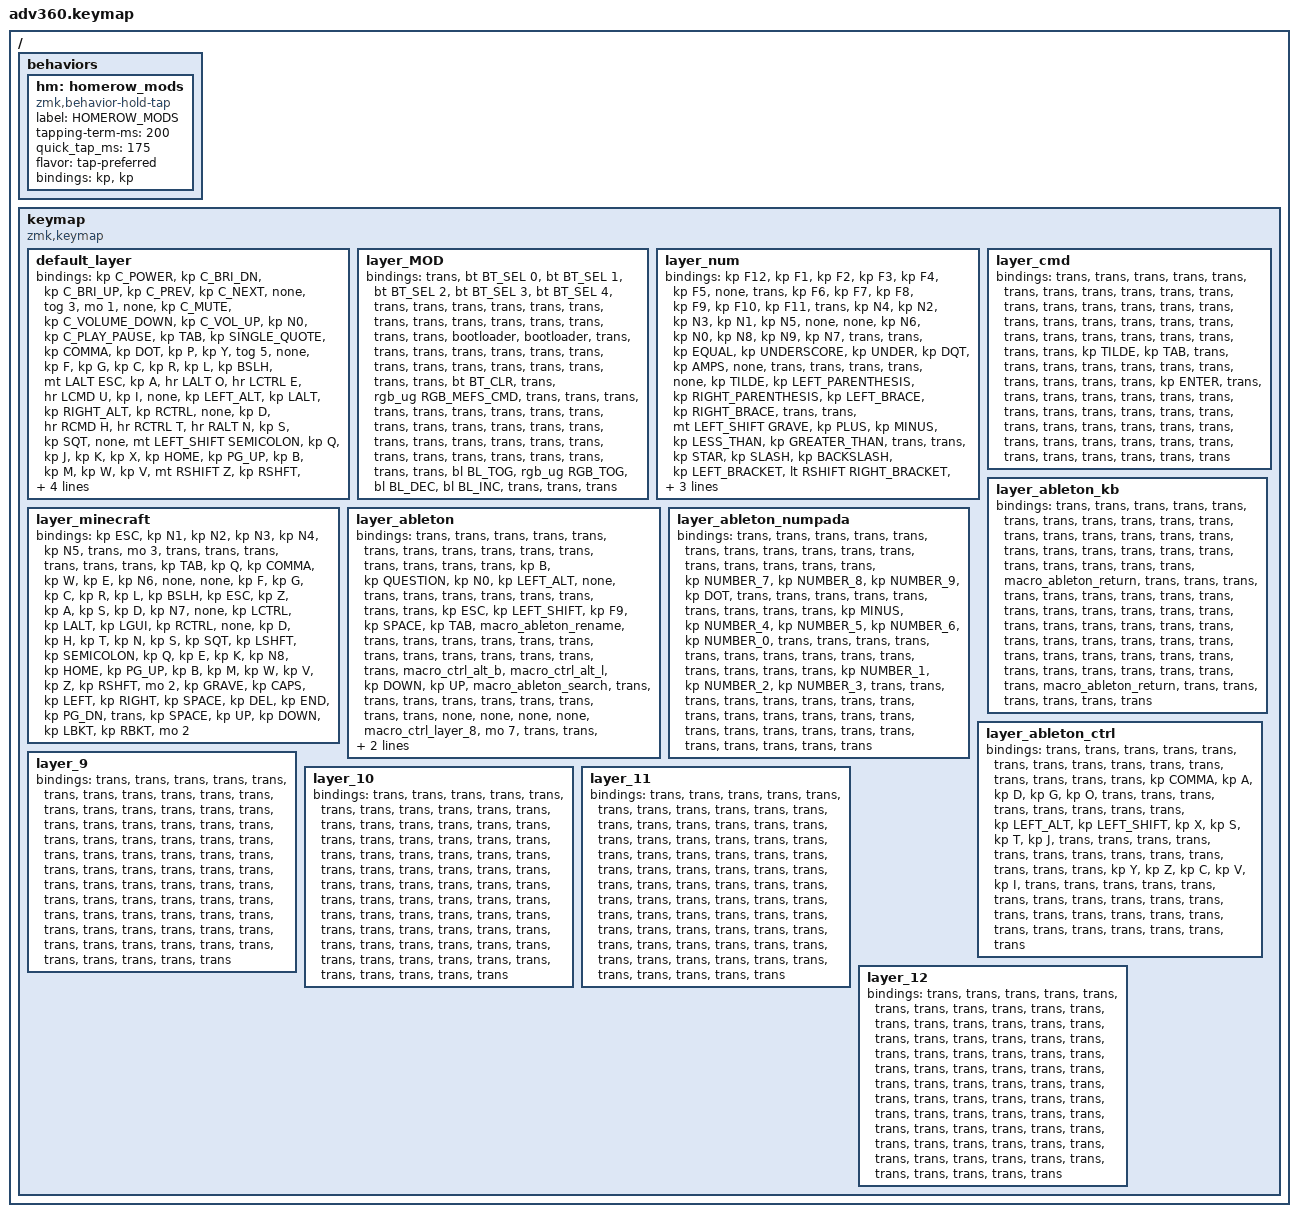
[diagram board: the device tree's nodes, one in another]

/*
 * Copyright (c) 2020 The ZMK Contributors
 *
 * SPDX-License-Identifier: MIT
 */


/* THIS FILE WAS GENERATED!
 *
 * This file was generated automatically. You may or may not want to
 * edit it directly.
 */

#include <behaviors.dtsi>
#include <dt-bindings/zmk/keys.h>
#include <dt-bindings/zmk/bt.h>
#include <dt-bindings/zmk/rgb.h>
#include <dt-bindings/zmk/backlight.h>

/ {
  behaviors {
    #include "macros.dtsi"
    #include "version.dtsi"

    hm: homerow_mods {
        compatible = "zmk,behavior-hold-tap";
        label = "HOMEROW_MODS";
        #binding-cells = <2>;
        tapping-term-ms = <200>;
        quick_tap_ms = <175>;
        flavor = "tap-preferred";
        bindings = <&kp>, <&kp>;
    };
  };

    keymap {
        compatible = "zmk,keymap";


        default_layer {
            bindings = <
         &kp C_POWER              &kp C_BRI_DN  &kp C_BRI_UP  &kp C_PREV  &kp C_NEXT   &none                         &tog 3                                                                          &mo 1   &none  &kp C_MUTE  &kp C_VOLUME_DOWN  &kp C_VOL_UP    &kp N0  &kp C_PLAY_PAUSE
             &kp TAB          &kp SINGLE_QUOTE     &kp COMMA     &kp DOT       &kp P   &kp Y                         &tog 5                                                                          &none   &kp F       &kp G              &kp C         &kp R     &kp L          &kp BSLH
        &mt LALT ESC                     &kp A         &hr LALT O       &hr LCTRL E       &hr LCMD U   &kp I                          &none  &kp LEFT_ALT  &kp LALT                  &kp RIGHT_ALT    &kp RCTRL      &none   &kp D       &hr RCMD H         &hr RCTRL T   &hr RALT N &kp S           &kp SQT
 &none  &mt LEFT_SHIFT SEMICOLON         &kp Q       &kp J       &kp K   &kp X                                               &kp HOME                      &kp PG_UP                           &kp B       &kp M              &kp W         &kp V     &mt RSHIFT Z         &kp RSHFT
            &kp LCMD                 &kp GRAVE      &kp CAPS    &kp LEFT   &kp RIGHT                    &lt 2 BACKSPACE         &none     &none                      &kp PG_DN  &none  &lt 4 SPACE              &kp UP           &kp DOWN      &kp LBKT  &kp RBKT          &kp RCMD
            >;
        };

        layer_MOD {
            bindings = <
 &trans  &bt BT_SEL 0  &bt BT_SEL 1  &bt BT_SEL 2  &bt BT_SEL 3  &bt BT_SEL 4                 &trans                                                                        &trans  &trans      &trans      &trans  &trans  &trans  &trans
 &trans        &trans        &trans        &trans        &trans        &trans            &bootloader                                                                   &bootloader  &trans      &trans      &trans  &trans  &trans  &trans
 &trans        &trans        &trans        &trans        &trans        &trans                 &trans  &trans  &trans                  &bt BT_CLR      &trans  &rgb_ug RGB_MEFS_CMD  &trans      &trans      &trans  &trans  &trans  &trans
 &trans        &trans        &trans        &trans        &trans        &trans                                 &trans                      &trans                                    &trans      &trans      &trans  &trans  &trans  &trans
 &trans        &trans        &trans        &trans        &trans                               &trans  &trans  &trans                      &trans  &bl BL_TOG       &rgb_ug RGB_TOG          &bl BL_DEC  &bl BL_INC  &trans  &trans  &trans
            >;
        };

        layer_num {
            bindings = <
 &kp F12     &kp F1          &kp F2     &kp F3         &kp F4            &kp F5             &none                                                          &trans     &kp F6                &kp F7                 &kp F8            &kp F9            &kp F10  &kp F11
  &trans     &kp N4          &kp N2     &kp N3         &kp N1            &kp N5             &none                                                           &none     &kp N6                &kp N0                 &kp N8            &kp N9             &kp N7   &trans
  &trans  &kp EQUAL  &kp UNDERSCORE  &kp UNDER        &kp DQT          &kp AMPS             &none  &trans  &trans                  &trans          &trans   &none  &kp TILDE  &kp LEFT_PARENTHESIS  &kp RIGHT_PARENTHESIS    &kp LEFT_BRACE    &kp RIGHT_BRACE   &trans
  &trans  &mt LEFT_SHIFT GRAVE        &kp PLUS  &kp MINUS  &kp LESS_THAN  &kp GREATER_THAN                            &trans                  &trans                           &kp STAR             &kp SLASH          &kp BACKSLASH  &kp LEFT_BRACKET  &lt RSHIFT RIGHT_BRACKET   &trans
  &trans     &trans          &trans     &trans         &trans                              &trans  &trans  &trans                  &trans  &mt RCMD ENTER  &trans                           &trans                 &trans            &trans             &trans   &trans
            >;
        };

        layer_minecraft {
            bindings = <
        &kp ESC          &kp N1     &kp N2    &kp N3     &kp N4  &kp N5               &trans                                                                 &mo 3  &trans  &trans    &trans    &trans    &trans     &trans
        &kp TAB           &kp Q  &kp COMMA     &kp W      &kp E  &kp N6                &none                                                                 &none   &kp F   &kp G     &kp C     &kp R     &kp L   &kp BSLH
        &kp ESC           &kp Z      &kp A     &kp S      &kp D  &kp N7                &none  &kp LCTRL  &kp LALT                   &kp LGUI  &kp RCTRL      &none   &kp D   &kp H     &kp T     &kp N     &kp S    &kp SQT
      &kp LSHFT   &kp SEMICOLON      &kp Q     &kp E      &kp K  &kp N8                                  &kp HOME                  &kp PG_UP                         &kp B   &kp M     &kp W     &kp V     &kp Z  &kp RSHFT
          &mo 2       &kp GRAVE   &kp CAPS  &kp LEFT  &kp RIGHT                    &kp SPACE    &kp DEL   &kp END                  &kp PG_DN     &trans  &kp SPACE          &kp UP  &kp DOWN  &kp LBKT  &kp RBKT      &mo 2
            >;
        };

        layer_cmd {
            bindings = <
 &trans  &trans  &trans     &trans   &trans  &trans            &trans                                                  &trans  &trans    &trans  &trans  &trans  &trans  &trans
 &trans  &trans  &trans     &trans   &trans  &trans            &trans                                                  &trans  &trans    &trans  &trans  &trans  &trans  &trans
 &trans  &trans  &trans  &kp TILDE  &kp TAB  &trans            &trans  &trans  &trans                  &trans  &trans  &trans  &trans    &trans  &trans  &trans  &kp ENTER &trans
 &trans  &trans  &trans     &trans   &trans  &trans                            &trans                  &trans                  &trans    &trans  &trans  &trans  &trans  &trans
 &trans  &trans  &trans     &trans   &trans                    &trans  &trans  &trans                  &trans  &trans  &trans            &trans  &trans  &trans  &trans  &trans
            >;
        };

        layer_ableton {
            bindings = <
  &trans             &trans             &trans     &trans        &trans                 &trans                         &trans                                                             &trans  &trans  &trans  &trans  &trans  &trans  &trans
  &trans              &kp B       &kp QUESTION     &kp N0  &kp LEFT_ALT                  &none                         &trans                                                             &trans  &trans  &trans  &trans  &trans  &trans  &trans
 &kp ESC     &kp LEFT_SHIFT             &kp F9  &kp SPACE       &kp TAB  &macro_ableton_rename                         &trans  &trans  &trans                  &trans             &trans  &trans  &trans  &trans  &trans  &trans  &trans  &trans
  &trans  &macro_ctrl_alt_b  &macro_ctrl_alt_l   &kp DOWN        &kp UP  &macro_ableton_search                                         &trans                  &trans                             &trans  &trans  &trans  &trans  &trans  &trans
  &trans              &none              &none      &none         &none                                    &macro_ctrl_layer_8  &mo 7  &trans                  &trans  &macro_ableton_kb  &trans          &trans  &trans  &trans  &trans  &trans
            >;
        };

        layer_ableton_kb {
            bindings = <
                &trans  &trans  &trans  &trans  &trans  &trans            &trans                                                                 &trans  &trans  &trans  &trans  &trans  &trans  &trans
                &trans  &trans  &trans  &trans  &trans  &trans            &trans                                                                 &trans  &trans  &trans  &trans  &trans  &trans  &trans
 &macro_ableton_return  &trans  &trans  &trans  &trans  &trans            &trans  &trans  &trans                  &trans                 &trans  &trans  &trans  &trans  &trans  &trans  &trans  &trans
                &trans  &trans  &trans  &trans  &trans  &trans                            &trans                  &trans                                 &trans  &trans  &trans  &trans  &trans  &trans
                &trans  &trans  &trans  &trans  &trans                    &trans  &trans  &trans                  &trans  &macro_ableton_return  &trans          &trans  &trans  &trans  &trans  &trans
            >;
        };

        layer_ableton_numpada {
            bindings = <
 &trans     &trans        &trans        &trans        &trans        &trans            &trans                                                  &trans  &trans  &trans  &trans  &trans  &trans  &trans
 &trans     &trans  &kp NUMBER_7  &kp NUMBER_8  &kp NUMBER_9       &kp DOT            &trans                                                  &trans  &trans  &trans  &trans  &trans  &trans  &trans
 &trans  &kp MINUS  &kp NUMBER_4  &kp NUMBER_5  &kp NUMBER_6  &kp NUMBER_0            &trans  &trans  &trans                  &trans  &trans  &trans  &trans  &trans  &trans  &trans  &trans  &trans
 &trans     &trans  &kp NUMBER_1  &kp NUMBER_2  &kp NUMBER_3        &trans                            &trans                  &trans                  &trans  &trans  &trans  &trans  &trans  &trans
 &trans     &trans        &trans        &trans        &trans                          &trans  &trans  &trans                  &trans  &trans  &trans          &trans  &trans  &trans  &trans  &trans
            >;
        };

        layer_ableton_ctrl {
            bindings = <
       &trans          &trans  &trans  &trans  &trans  &trans            &trans                                                  &trans  &trans  &trans  &trans  &trans  &trans  &trans
       &trans       &kp COMMA   &kp A   &kp D   &kp G   &kp O            &trans                                                  &trans  &trans  &trans  &trans  &trans  &trans  &trans
 &kp LEFT_ALT  &kp LEFT_SHIFT   &kp X   &kp S   &kp T   &kp J            &trans  &trans  &trans                  &trans  &trans  &trans  &trans  &trans  &trans  &trans  &trans  &trans
       &trans           &kp Y   &kp Z   &kp C   &kp V   &kp I                            &trans                  &trans                  &trans  &trans  &trans  &trans  &trans  &trans
       &trans          &trans  &trans  &trans  &trans                    &trans  &trans  &trans                  &trans  &trans  &trans          &trans  &trans  &trans  &trans  &trans
            >;
        };

        layer_9 {
            bindings = <
 &trans  &trans  &trans  &trans  &trans  &trans            &trans                                                  &trans  &trans  &trans  &trans  &trans  &trans  &trans
 &trans  &trans  &trans  &trans  &trans  &trans            &trans                                                  &trans  &trans  &trans  &trans  &trans  &trans  &trans
 &trans  &trans  &trans  &trans  &trans  &trans            &trans  &trans  &trans                  &trans  &trans  &trans  &trans  &trans  &trans  &trans  &trans  &trans
 &trans  &trans  &trans  &trans  &trans  &trans                            &trans                  &trans                  &trans  &trans  &trans  &trans  &trans  &trans
 &trans  &trans  &trans  &trans  &trans                    &trans  &trans  &trans                  &trans  &trans  &trans          &trans  &trans  &trans  &trans  &trans
            >;
        };

        layer_10 {
            bindings = <
 &trans  &trans  &trans  &trans  &trans  &trans            &trans                                                  &trans  &trans  &trans  &trans  &trans  &trans  &trans
 &trans  &trans  &trans  &trans  &trans  &trans            &trans                                                  &trans  &trans  &trans  &trans  &trans  &trans  &trans
 &trans  &trans  &trans  &trans  &trans  &trans            &trans  &trans  &trans                  &trans  &trans  &trans  &trans  &trans  &trans  &trans  &trans  &trans
 &trans  &trans  &trans  &trans  &trans  &trans                            &trans                  &trans                  &trans  &trans  &trans  &trans  &trans  &trans
 &trans  &trans  &trans  &trans  &trans                    &trans  &trans  &trans                  &trans  &trans  &trans          &trans  &trans  &trans  &trans  &trans
            >;
        };

        layer_11 {
            bindings = <
 &trans  &trans  &trans  &trans  &trans  &trans            &trans                                                  &trans  &trans  &trans  &trans  &trans  &trans  &trans
 &trans  &trans  &trans  &trans  &trans  &trans            &trans                                                  &trans  &trans  &trans  &trans  &trans  &trans  &trans
 &trans  &trans  &trans  &trans  &trans  &trans            &trans  &trans  &trans                  &trans  &trans  &trans  &trans  &trans  &trans  &trans  &trans  &trans
 &trans  &trans  &trans  &trans  &trans  &trans                            &trans                  &trans                  &trans  &trans  &trans  &trans  &trans  &trans
 &trans  &trans  &trans  &trans  &trans                    &trans  &trans  &trans                  &trans  &trans  &trans          &trans  &trans  &trans  &trans  &trans
            >;
        };

        layer_12 {
            bindings = <
 &trans  &trans  &trans  &trans  &trans  &trans            &trans                                                  &trans  &trans  &trans  &trans  &trans  &trans  &trans
 &trans  &trans  &trans  &trans  &trans  &trans            &trans                                                  &trans  &trans  &trans  &trans  &trans  &trans  &trans
 &trans  &trans  &trans  &trans  &trans  &trans            &trans  &trans  &trans                  &trans  &trans  &trans  &trans  &trans  &trans  &trans  &trans  &trans
 &trans  &trans  &trans  &trans  &trans  &trans                            &trans                  &trans                  &trans  &trans  &trans  &trans  &trans  &trans
 &trans  &trans  &trans  &trans  &trans                    &trans  &trans  &trans                  &trans  &trans  &trans          &trans  &trans  &trans  &trans  &trans
            >;
        };

    };
};
